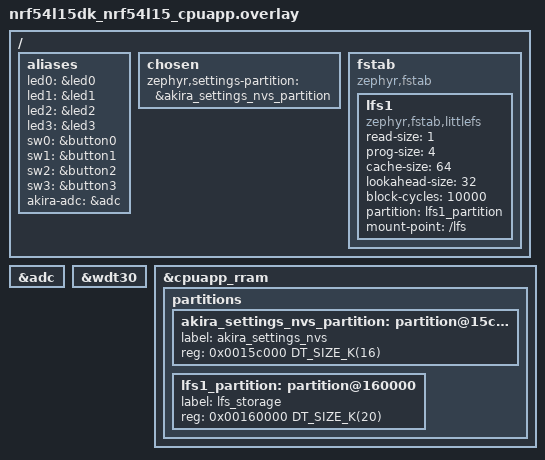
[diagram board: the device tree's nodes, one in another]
/*
 * Nordic nRF54L15 DK Device Tree Overlay for AkiraOS
 * Board: nrf54l15dk/nrf54l15/cpuapp
 * 
 * Note: The base board already has console, GPIO, radio, etc. configured.
 * This overlay just adds AkiraOS-specific settings.
 */

/ {
    aliases {
        /* Use the existing board LEDs and buttons */
        led0 = &led0;
        led1 = &led1;
        led2 = &led2;
        led3 = &led3;
        sw0 = &button0;
        sw1 = &button1;
        sw2 = &button2;
        sw3 = &button3;
        akira-adc = &adc;
    };
};

/* I2C and SPI require pinctrl configuration - disabled until needed
 * To enable, add proper pinctrl nodes based on your hardware connections
 */

/* Enable ADC */
&adc {
    status = "okay";
};

/* Enable watchdog */
&wdt30 {
    status = "okay";
};

/* Remap the default storage_partition into AkiraOS-specific partitions.
 * nRF54L15 cpuapp RRAM: 0x00000–0x164FFF (slots end at 0x15bFFF).
 * Original storage_partition: 0x15c000 (36KB) — split into:
 *   16KB NVS for settings, 20KB LittleFS for app storage.
 */
&cpuapp_rram {
    partitions {
        akira_settings_nvs_partition: partition@15c000 {
            label = "akira_settings_nvs";
            reg = <0x0015c000 DT_SIZE_K(16)>;
        };

        lfs1_partition: partition@160000 {
            label = "lfs_storage";
            reg = <0x00160000 DT_SIZE_K(20)>;
        };
    };
};

/ {
    chosen {
        zephyr,settings-partition = &akira_settings_nvs_partition;
    };

    fstab {
        compatible = "zephyr,fstab";

        lfs1: lfs1 {
            compatible = "zephyr,fstab,littlefs";
            read-size = <1>;
            prog-size = <4>;
            cache-size = <64>;
            lookahead-size = <32>;
            block-cycles = <10000>;
            partition = <&lfs1_partition>;
            mount-point = "/lfs";
        };
    };
};
